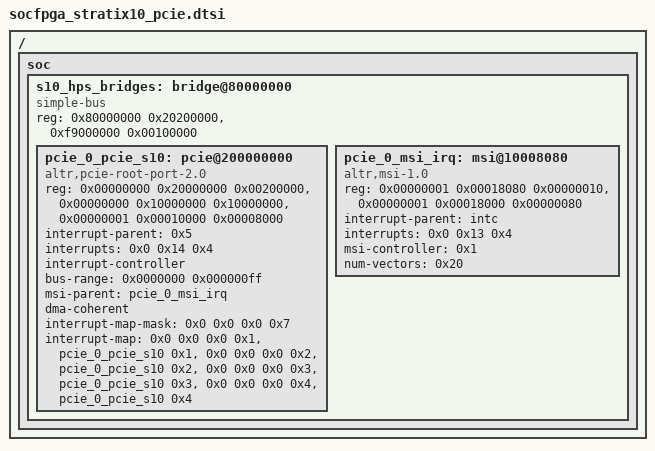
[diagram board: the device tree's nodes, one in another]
/{
         soc{
                  s10_hps_bridges: bridge@80000000 {
                        compatible = "simple-bus";
                        reg = <0x80000000 0x20200000>,
                              <0xf9000000 0x00100000>;
                        reg-names = "axi_h2f", "axi_h2f_lw";
                        #address-cells = <0x2>;
                        #size-cells = <0x1>;
                        ranges = <0x00000000 0x00000000 0x80000000 0x00040000>,
                                 <0x00000000 0x10000000 0x90000000 0x10000000>,
                                 <0x00000000 0x20000000 0xa0000000 0x00200000>,
                                 <0x00000001 0x00010000 0xf9010000 0x00008000>,
                                 <0x00000001 0x00018000 0xf9018000 0x00000080>, 
                                 <0x00000001 0x00018080 0xf9018080 0x00000010>;

                       pcie_0_pcie_s10: pcie@200000000 {
                                       compatible = "altr,pcie-root-port-2.0";
                                       reg = <0x00000000 0x20000000 0x00200000>,
                                             <0x00000000 0x10000000 0x10000000>,
                                             <0x00000001 0x00010000 0x00008000>;
                                       reg-names = "Hip", "Txs", "Cra";
                                       interrupt-parent = <0x5>;
                                       interrupts = <0x0 0x14 0x4>;
                                       interrupt-controller;
                                       #interrupt-cells = <0x1>;
                                       device_type = "pci";
                                       bus-range = <0x0000000 0x000000ff>;
                                       ranges = <0x82000000 0x00000000 0x00000000 0x00000000 0x10000000 0x00000000 0x10000000>;
                                       msi-parent = <&pcie_0_msi_irq>;
                                       #address-cells = <0x3>;
                                       #size-cells = <0x2>;
                                       dma-coherent;
                                       interrupt-map-mask = <0x0 0x0 0x0 0x7>;
                                       interrupt-map = <0x0 0x0 0x0 0x1 &pcie_0_pcie_s10 0x1>,
                                                      <0x0 0x0 0x0 0x2 &pcie_0_pcie_s10 0x2>,
                                                      <0x0 0x0 0x0 0x3 &pcie_0_pcie_s10 0x3>,
                                                      <0x0 0x0 0x0 0x4 &pcie_0_pcie_s10 0x4>;
                                       }; //end pcie@0x010000000 (pcie_0_pcie_s10)

                          pcie_0_msi_irq: msi@10008080 {
                                       compatible = "altr,msi-1.0";
                                       reg = <0x00000001 0x00018080 0x00000010>,
                                             <0x00000001 0x00018000 0x00000080>;
                                       reg-names = "csr", "vector_slave";
                                       interrupt-parent = <&intc>;
                                       interrupts = <0x0 0x13 0x4>;
                                       msi-controller = <0x1>;
                                       num-vectors = <0x20>;
                                       }; //end msi@0x100008000 (pcie_0_msi_irq)
                        };

         };
};
